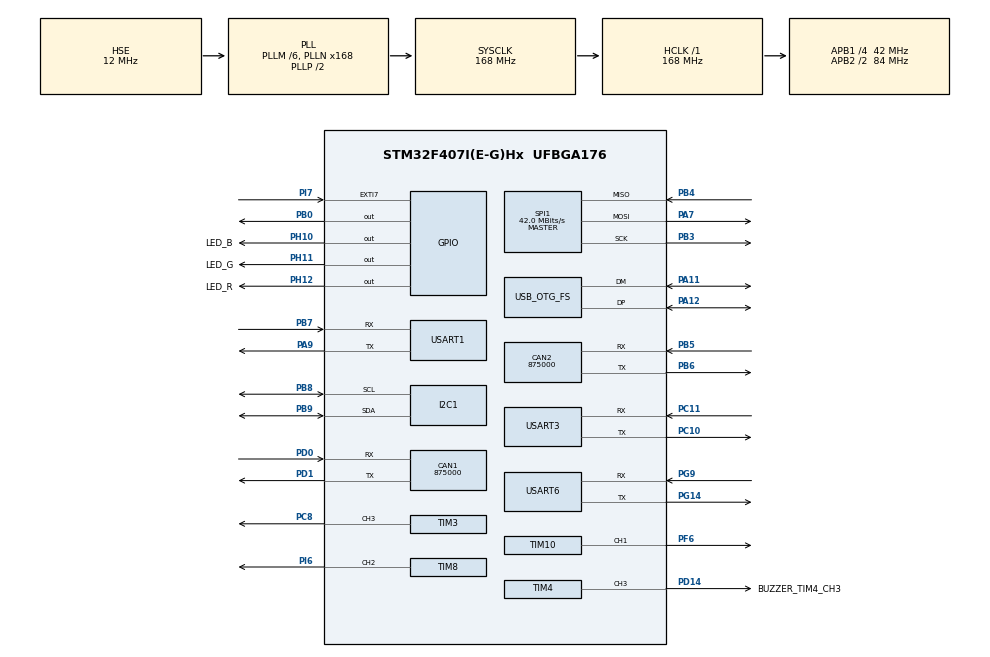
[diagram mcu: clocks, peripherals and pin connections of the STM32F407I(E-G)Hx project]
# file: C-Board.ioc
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CAN1.CalculateBaudRate=875000
CAN1.CalculateTimeBit=1142
CAN1.CalculateTimeQuantum=380.95238095238096
CAN2.CalculateBaudRate=875000
CAN2.CalculateTimeBit=1142
CAN2.CalculateTimeQuantum=380.95238095238096
Mcu.Family=STM32F4
Mcu.Name=STM32F407I(E-G)Hx
Mcu.Package=UFBGA176
NVIC.OTG_FS_IRQn=true\:0\:0\:false\:false\:true\:false\:true\:true
NVIC.PriorityGroup=NVIC_PRIORITYGROUP_4
PA11.Mode=Device_Only
PA11.Signal=USB_OTG_FS_DM
PA12.Mode=Device_Only
PA12.Signal=USB_OTG_FS_DP
PA13.Mode=Serial_Wire
PA13.Signal=SYS_JTMS-SWDIO
PA14.Mode=Serial_Wire
PA14.Signal=SYS_JTCK-SWCLK
PA7.Mode=Full_Duplex_Master
PA7.Signal=SPI1_MOSI
PA9.Mode=Asynchronous
PA9.Signal=USART1_TX
PB0.Signal=GPIO_Output
PB3.Mode=Full_Duplex_Master
PB3.Signal=SPI1_SCK
PB4.Mode=Full_Duplex_Master
PB4.Signal=SPI1_MISO
PB5.Mode=CAN_Activate
PB5.Signal=CAN2_RX
PB6.Mode=CAN_Activate
PB6.Signal=CAN2_TX
PB7.Mode=Asynchronous
PB7.Signal=USART1_RX
PB8.Mode=I2C
PB8.Signal=I2C1_SCL
PB9.Mode=I2C
PB9.Signal=I2C1_SDA
PC10.Mode=Asynchronous
PC10.Signal=USART3_TX
PC11.Mode=Asynchronous
PC11.Signal=USART3_RX
PC8.Signal=S_TIM3_CH3
PD0.Mode=CAN_Activate
PD0.Signal=CAN1_RX
PD1.Mode=CAN_Activate
PD1.Signal=CAN1_TX
PD14.GPIO_Label=BUZZER_TIM4_CH3
PD14.Signal=S_TIM4_CH3
PF6.Signal=S_TIM10_CH1
PG14.Mode=Asynchronous
PG14.Signal=USART6_TX
PG9.Mode=Asynchronous
PG9.Signal=USART6_RX
PH0-OSC_IN.Mode=HSE-External-Oscillator
PH0-OSC_IN.Signal=RCC_OSC_IN
PH1-OSC_OUT.Mode=HSE-External-Oscillator
PH1-OSC_OUT.Signal=RCC_OSC_OUT
PH10.GPIO_Label=LED_B
PH10.Signal=GPIO_Output
PH11.GPIO_Label=LED_G
PH11.Signal=GPIO_Output
PH12.GPIO_Label=LED_R
PH12.Signal=GPIO_Output
PI6.Signal=S_TIM8_CH2
PI7.Signal=GPXTI7
ProjectManager.HeapSize=0x200
ProjectManager.StackSize=0x400
ProjectManager.TargetToolchain=MDK-ARM V5.32
RCC.48MHZClocksFreq_Value=48000000
RCC.AHBFreq_Value=168000000
RCC.APB1CLKDivider=RCC_HCLK_DIV4
RCC.APB1Freq_Value=42000000
RCC.APB1TimFreq_Value=84000000
RCC.APB2CLKDivider=RCC_HCLK_DIV2
RCC.APB2Freq_Value=84000000
RCC.APB2TimFreq_Value=168000000
RCC.CortexFreq_Value=168000000
RCC.HCLKFreq_Value=168000000
RCC.HSE_VALUE=12000000
RCC.HSI_VALUE=16000000
RCC.LSE_VALUE=32768
RCC.PLLM=6
RCC.PLLN=168
RCC.PLLQ=7
RCC.SYSCLKFreq_VALUE=168000000
RCC.SYSCLKSource=RCC_SYSCLKSOURCE_PLLCLK
RCC.VCOOutputFreq_Value=336000000
SH.S_TIM10_CH1.0=TIM10_CH1,PWM Generation1 CH1
SH.S_TIM3_CH3.0=TIM3_CH3,PWM Generation3 CH3
SH.S_TIM4_CH3.0=TIM4_CH3,PWM Generation3 CH3
SH.S_TIM8_CH2.0=TIM8_CH2,PWM Generation2 CH2
SPI1.CalculateBaudRate=42.0 MBits/s
SPI1.Direction=SPI_DIRECTION_2LINES
SPI1.Mode=SPI_MODE_MASTER
SPI1.VirtualType=VM_MASTER
TIM10.Channel=TIM_CHANNEL_1
TIM3.Channel-PWM\ Generation3\ CH3=TIM_CHANNEL_3
TIM3.Period=100
TIM3.Prescaler=84-1
TIM3.Pulse-PWM\ Generation3\ CH3=50
TIM4.Channel-PWM\ Generation3\ CH3=TIM_CHANNEL_3
TIM8.Channel-PWM\ Generation2\ CH2=TIM_CHANNEL_2
USART1.VirtualMode=VM_ASYNC
USART3.VirtualMode=VM_ASYNC
USART6.VirtualMode=VM_ASYNC
USB_DEVICE.CLASS_NAME_FS=CDC
USB_DEVICE.VirtualMode-CDC_FS=Cdc
USB_DEVICE.VirtualModeFS=Cdc_FS
USB_OTG_FS.VirtualMode=Device_Only
VP_TIM10_VS_ClockSourceINT.Mode=Enable_Timer
VP_USB_DEVICE_VS_USB_DEVICE_CDC_FS.Mode=CDC_FS
board=custom

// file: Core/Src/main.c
/* USER CODE BEGIN Header */
/**
  ******************************************************************************
  * @file           : main.c
  * @brief          : Main program body
  ******************************************************************************
  * @attention
  *
  * Copyright (c) 2024 STMicroelectronics.
  * All rights reserved.
  *
  * This software is licensed under terms that can be found in the LICENSE file
  * in the root directory of this software component.
  * If no LICENSE file comes with this software, it is provided AS-IS.
  *
  ******************************************************************************
  */
/* USER CODE END Header */
#include "main.h"
#include "can.h"
#include "i2c.h"
#include "spi.h"
#include "tim.h"
#include "usart.h"
#include "usb_device.h"
#include "gpio.h"

void SystemClock_Config(void);

int main(void)
{

  /* MCU Configuration--------------------------------------------------------*/

  /* Reset of all peripherals, Initializes the Flash interface and the Systick. */
  HAL_Init();

  /* Configure the system clock */
  SystemClock_Config();

  /* Initialize all configured peripherals */
  MX_GPIO_Init();
  MX_USB_DEVICE_Init();
  MX_CAN1_Init();
  MX_CAN2_Init();
  MX_I2C1_Init();
  MX_SPI1_Init();
  MX_TIM3_Init();
  MX_TIM4_Init();
  MX_TIM8_Init();
  MX_TIM10_Init();
  MX_USART1_UART_Init();
  MX_USART3_UART_Init();
  MX_USART6_UART_Init();
  /* USER CODE BEGIN 2 */
  HAL_TIM_PWM_Start(&htim3 ,TIM_CHANNEL_3 );
  /* USER CODE END 2 */

  /* Infinite loop */
  while (1)
  {

    /* USER CODE BEGIN 3 */

	for (int i = 0; i < 100; i++)
	   {
        __HAL_TIM_SET_COMPARE(&htim3, TIM_CHANNEL_3, i);
        HAL_Delay(8);
	  }
	  for (int i = 99;i >= 0; i--)
	    {
        __HAL_TIM_SET_COMPARE(&htim3, TIM_CHANNEL_3, i);
        HAL_Delay(8);
	  }

	  HAL_GPIO_WritePin (LED_G_GPIO_Port ,LED_G_Pin ,GPIO_PIN_SET );
//	  HAL_Delay (1000);
//	  HAL_GPIO_WritePin (LED_G_GPIO_Port ,LED_G_Pin ,GPIO_PIN_SET );
//	  HAL_Delay (1000);
//	  HAL_GPIO_WritePin (LASER_GPIO_Port ,LASER_Pin ,GPIO_PIN_RESET );
//	  HAL_Delay (1000);
//	  HAL_GPIO_WritePin (LASER_GPIO_Port ,LASER_Pin ,GPIO_PIN_SET );
//	  HAL_Delay (1000);

  }
  /* USER CODE END 3 */
}

void SystemClock_Config(void)
{
  RCC_OscInitTypeDef RCC_OscInitStruct = {0};
  RCC_ClkInitTypeDef RCC_ClkInitStruct = {0};

  /** Configure the main internal regulator output voltage
  */
  __HAL_RCC_PWR_CLK_ENABLE();
  __HAL_PWR_VOLTAGESCALING_CONFIG(PWR_REGULATOR_VOLTAGE_SCALE1);

  /** Initializes the RCC Oscillators according to the specified parameters
  * in the RCC_OscInitTypeDef structure.
  */
  RCC_OscInitStruct.OscillatorType = RCC_OSCILLATORTYPE_HSE;
  RCC_OscInitStruct.HSEState = RCC_HSE_ON;
  RCC_OscInitStruct.PLL.PLLState = RCC_PLL_ON;
  RCC_OscInitStruct.PLL.PLLSource = RCC_PLLSOURCE_HSE;
  RCC_OscInitStruct.PLL.PLLM = 6;
  RCC_OscInitStruct.PLL.PLLN = 168;
  RCC_OscInitStruct.PLL.PLLP = RCC_PLLP_DIV2;
  RCC_OscInitStruct.PLL.PLLQ = 7;
  if (HAL_RCC_OscConfig(&RCC_OscInitStruct) != HAL_OK)
  {
    Error_Handler();
  }

  /** Initializes the CPU, AHB and APB buses clocks
  */
  RCC_ClkInitStruct.ClockType = RCC_CLOCKTYPE_HCLK|RCC_CLOCKTYPE_SYSCLK
                              |RCC_CLOCKTYPE_PCLK1|RCC_CLOCKTYPE_PCLK2;
  RCC_ClkInitStruct.SYSCLKSource = RCC_SYSCLKSOURCE_PLLCLK;
  RCC_ClkInitStruct.AHBCLKDivider = RCC_SYSCLK_DIV1;
  RCC_ClkInitStruct.APB1CLKDivider = RCC_HCLK_DIV4;
  RCC_ClkInitStruct.APB2CLKDivider = RCC_HCLK_DIV2;

  if (HAL_RCC_ClockConfig(&RCC_ClkInitStruct, FLASH_LATENCY_5) != HAL_OK)
  {
    Error_Handler();
  }
}

void Error_Handler(void)
{
  __disable_irq();
  while (1)
  {
  }
}
